AUTOSAR XML (schema 314)
package /ComponentType
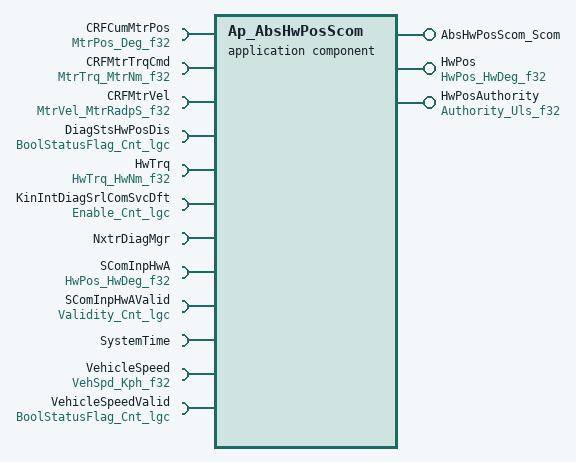
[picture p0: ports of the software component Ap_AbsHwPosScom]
  application software component type Ap_AbsHwPosScom
    provide port AbsHwPosScom_Scom: provided-com-specs=[{operation=HwPosSrvRead, queue-length=1}, {operation=HwPosSrvSetToZero, queue-length=1}], provided-interface=AbsHwPosScom_Scom
    provide port HwPos: unqueued-sender-com-spec{data-element=HwDeg_f32, can-invalidate=false, init-value=D_ZERO_ULS_F32}, provided-interface=HwPos_HwDeg_f32
    provide port HwPosAuthority: unqueued-sender-com-spec{data-element=Uls_f32, can-invalidate=false, init-value=D_ZERO_ULS_F32}, provided-interface=Authority_Uls_f32
    12 x require port:
      CRFCumMtrPos: unqueued-receiver-com-spec{data-element=Deg_f32, init-value=D_ZERO_ULS_F32}, required-interface=MtrPos_Deg_f32
      CRFMtrTrqCmd: unqueued-receiver-com-spec{data-element=MtrNm_f32, init-value=D_ZERO_ULS_F32}, required-interface=MtrTrq_MtrNm_f32
      CRFMtrVel: unqueued-receiver-com-spec{data-element=MtrRadpS_f32, init-value=D_ZERO_ULS_F32}, required-interface=MtrVel_MtrRadpS_f32
      DiagStsHwPosDis: unqueued-receiver-com-spec{data-element=Cnt_lgc, init-value=D_FALSE_CNT_LGC}, required-interface=BoolStatusFlag_Cnt_lgc
      HwTrq: unqueued-receiver-com-spec{data-element=HwNm_f32, init-value=D_ZERO_ULS_F32}, required-interface=HwTrq_HwNm_f32
      KinIntDiagSrlComSvcDft: unqueued-receiver-com-spec{data-element=Cnt_lgc, init-value=D_FALSE_CNT_LGC}, required-interface=Enable_Cnt_lgc
      NxtrDiagMgr: required-com-specs=[GetNTCActive, GetNTCFailed, GetNTCStatus, SetNTCStatus], required-interface=NxtrDiagMgr
      SComInpHwA: unqueued-receiver-com-spec{data-element=HwDeg_f32, init-value=D_ZERO_ULS_F32}, required-interface=HwPos_HwDeg_f32
      SComInpHwAValid: unqueued-receiver-com-spec{data-element=Cnt_lgc, init-value=D_FALSE_CNT_LGC}, required-interface=Validity_Cnt_lgc
      SystemTime: required-interface=SystemTime
        required-com-specs:
          DtrmnElapsedTime_mS_u16
          DtrmnElapsedTime_mS_u32
          DtrmnElapsedTime_uS_u16
          DtrmnElapsedTime_uS_u32
          GetSystemTime_mS_u32
          GetSystemTime_uS_u32
      VehicleSpeed: unqueued-receiver-com-spec{data-element=Kph_f32, init-value=D_ZERO_ULS_F32}, required-interface=VehSpd_Kph_f32
      VehicleSpeedValid: unqueued-receiver-com-spec{data-element=Cnt_lgc, init-value=D_FALSE_CNT_LGC}, required-interface=BoolStatusFlag_Cnt_lgc
  internal behavior Ap_AbsHwPosScom_InternalBehavior: component=Ap_AbsHwPosScom
    4 x timing event:
      AbsHwPosScom_Init1_InitEvent: start-on-event=AbsHwPosScom_Init1, period=0
      TMT_AbsHwPosScom_Per1: start-on-event=AbsHwPosScom_Per1, period=0.002
      TMT_AbsHwPosScom_Per2: start-on-event=AbsHwPosScom_Per2, period=0.01
      TMT_AbsHwPosScom_Per3: start-on-event=AbsHwPosScom_Per3, period=0.01
    operation invoked event OIT_AbsHwPosScom_Scom_HwPosSrvRead_AbsHwPosScom_Scom_HwPosSrvRead: start-on-event=AbsHwPosScom_Scom_HwPosSrvRead, operation=AbsHwPosScom_Scom.HwPosSrvRead
    operation invoked event OIT_AbsHwPosScom_Scom_HwPosSrvSetToZero_AbsHwPosScom_Scom_HwPosSrvSetToZero: start-on-event=AbsHwPosScom_Scom_HwPosSrvSetToZero, operation=AbsHwPosScom_Scom.HwPosSrvSetToZero
    port-api-options:
      enable-take-address=false, indirect-api=false, port=AbsHwPosScom_Scom
      enable-take-address=false, indirect-api=false, port=CRFCumMtrPos
      enable-take-address=false, indirect-api=false, port=CRFMtrTrqCmd
      enable-take-address=false, indirect-api=false, port=CRFMtrVel
      enable-take-address=false, indirect-api=false, port=DiagStsHwPosDis
      enable-take-address=false, indirect-api=false, port=HwPos
      enable-take-address=false, indirect-api=false, port=HwPosAuthority
      enable-take-address=false, indirect-api=false, port=HwTrq
      enable-take-address=false, indirect-api=false, port=KinIntDiagSrlComSvcDft
      enable-take-address=false, indirect-api=false, port=NxtrDiagMgr
      enable-take-address=false, indirect-api=false, port=SComInpHwA
      enable-take-address=false, indirect-api=false, port=SComInpHwAValid
      enable-take-address=false, indirect-api=false, port=SystemTime
      enable-take-address=false, indirect-api=false, port=VehicleSpeed
      enable-take-address=false, indirect-api=false, port=VehicleSpeedValid
    6 x runnable:
      AbsHwPosScom_Init1
        sync call SC_NxtrDiagMgr_SetNTCStatus: operation=NxtrDiagMgr.SetNTCStatus, timeout=0
        sync call SC_SystemTime_GetSystemTime_mS_u32: operation=SystemTime.GetSystemTime_mS_u32, timeout=0
      AbsHwPosScom_Per1
        9 x data read access:
          READ_CRFCumMtrPos_Deg_f32: data-element=CRFCumMtrPos.Deg_f32
          READ_CRFMtrTrqCmd_MtrNm_f32: data-element=CRFMtrTrqCmd.MtrNm_f32
          READ_CRFMtrVel_MtrRadpS_f32: data-element=CRFMtrVel.MtrRadpS_f32
          READ_DiagStsHwPosDis_Cnt_lgc: data-element=DiagStsHwPosDis.Cnt_lgc
          READ_HwTrq_HwNm_f32: data-element=HwTrq.HwNm_f32
          READ_SComInpHwA_HwDeg_f32: data-element=SComInpHwA.HwDeg_f32
          READ_SComInpHwAValid_Cnt_lgc: data-element=SComInpHwAValid.Cnt_lgc
          READ_VehicleSpeed_Kph_f32: data-element=VehicleSpeed.Kph_f32
          READ_VehicleSpeedValid_Cnt_lgc: data-element=VehicleSpeedValid.Cnt_lgc
        data write access WRITE_HwPos_HwDeg_f32: data-element=HwPos.HwDeg_f32
        data write access WRITE_HwPosAuthority_Uls_f32: data-element=HwPosAuthority.Uls_f32
        sync call SC_SystemTime_DtrmnElapsedTime_mS_u16: operation=SystemTime.DtrmnElapsedTime_mS_u16, timeout=0
        sync call SC_SystemTime_GetSystemTime_mS_u32: operation=SystemTime.GetSystemTime_mS_u32, timeout=0
      AbsHwPosScom_Per2
        data read access READ_KinIntDiagSrlComSvcDft_Cnt_lgc: data-element=KinIntDiagSrlComSvcDft.Cnt_lgc
        sync call SC_NxtrDiagMgr_SetNTCStatus: operation=NxtrDiagMgr.SetNTCStatus, timeout=0
      AbsHwPosScom_Per3
        data read access READ_CRFMtrTrqCmd_MtrNm_f32: data-element=CRFMtrTrqCmd.MtrNm_f32
        data read access READ_HwTrq_HwNm_f32: data-element=HwTrq.HwNm_f32
      AbsHwPosScom_Scom_HwPosSrvRead
      AbsHwPosScom_Scom_HwPosSrvSetToZero
  swc implementation Ap_AbsHwPosScom_Implementation: behavior=Ap_AbsHwPosScom_InternalBehavior
    code-descriptors:
      code Code: type=SRC
